AUTOSAR XML (schema 4-0-3)
package /ComponentTypes
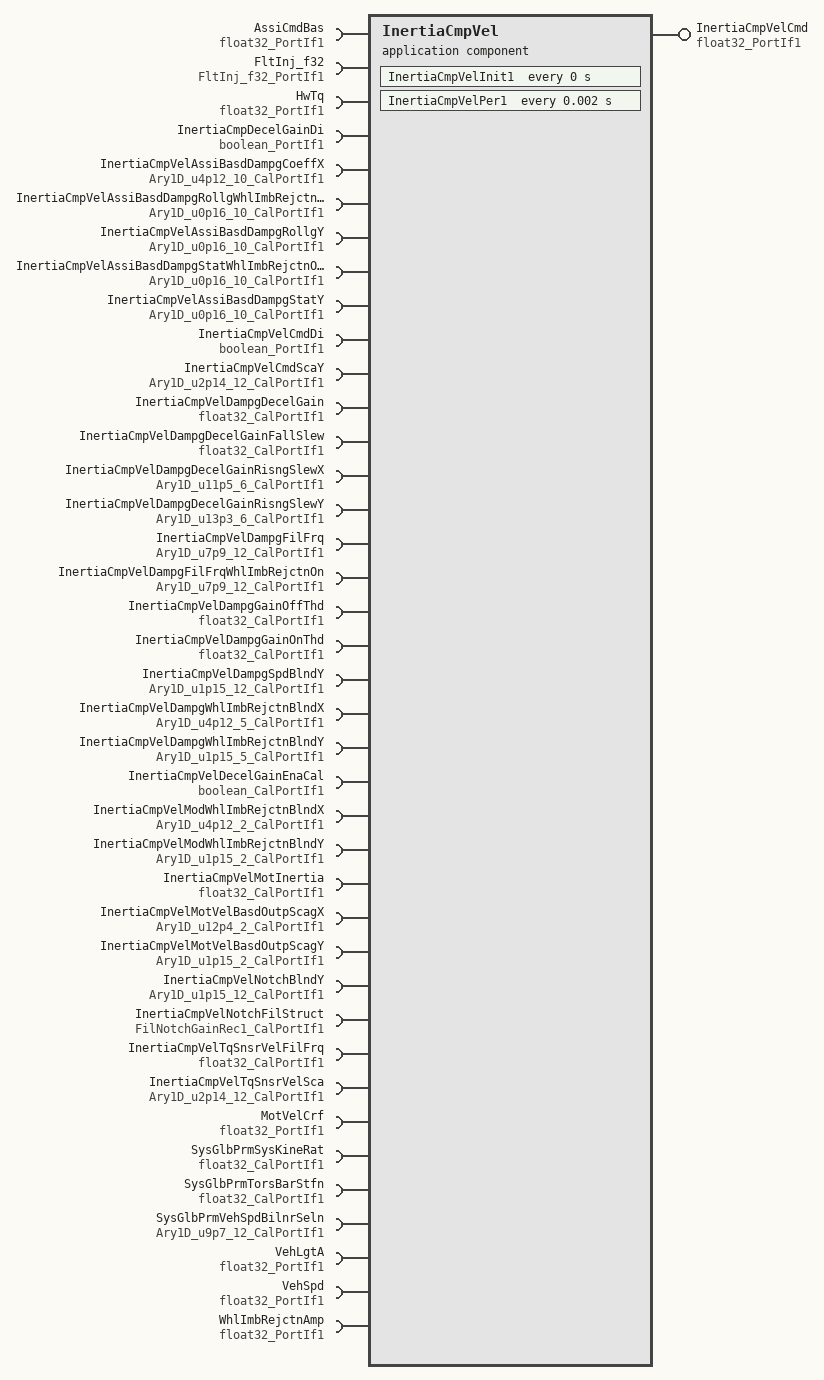
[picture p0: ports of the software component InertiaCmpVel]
  application sw component type InertiaCmpVel
    provide port InertiaCmpVelCmd: nonqueued-sender-com-spec{data-element=Val, init-value=0}, provided-interface=float32_PortIf1
    39 x require port:
      AssiCmdBas: nonqueued-receiver-com-spec{data-element=Val, filter=data-filter-type=ALWAYS, init-value=0}, required-interface=float32_PortIf1
      FltInj_f32: client-com-spec=Oper, required-interface=FltInj_f32_PortIf1
      HwTq: nonqueued-receiver-com-spec{data-element=Val, filter=data-filter-type=ALWAYS, init-value=0}, required-interface=float32_PortIf1
      InertiaCmpDecelGainDi: nonqueued-receiver-com-spec{data-element=Logl, filter=data-filter-type=ALWAYS, init-value=0}, required-interface=boolean_PortIf1
      InertiaCmpVelAssiBasdDampgCoeffX: parameter-require-com-spec{init-value=[0, 2048, 4096, 6144, 8192, 10240, 12288, 14336, 16384, 18432], parameter=Ary1D}, required-interface=Ary1D_u4p12_10_CalPortIf1
      InertiaCmpVelAssiBasdDampgRollgWhlImbRejctnOnY: parameter-require-com-spec{init-value=10 x 0, parameter=Ary1D}, required-interface=Ary1D_u0p16_10_CalPortIf1
      InertiaCmpVelAssiBasdDampgRollgY: parameter-require-com-spec{init-value=10 x 0, parameter=Ary1D}, required-interface=Ary1D_u0p16_10_CalPortIf1
      InertiaCmpVelAssiBasdDampgStatWhlImbRejctnOnY: parameter-require-com-spec{init-value=10 x 0, parameter=Ary1D}, required-interface=Ary1D_u0p16_10_CalPortIf1
      InertiaCmpVelAssiBasdDampgStatY: parameter-require-com-spec{init-value=10 x 0, parameter=Ary1D}, required-interface=Ary1D_u0p16_10_CalPortIf1
      InertiaCmpVelCmdDi: nonqueued-receiver-com-spec{data-element=Logl, filter=data-filter-type=ALWAYS, init-value=0}, required-interface=boolean_PortIf1
      InertiaCmpVelCmdScaY: parameter-require-com-spec{init-value=12 x 384, parameter=Ary1D}, required-interface=Ary1D_u2p14_12_CalPortIf1
      InertiaCmpVelDampgDecelGain: parameter-require-com-spec{init-value=1, parameter=Val}, required-interface=float32_CalPortIf1
      InertiaCmpVelDampgDecelGainFallSlew: parameter-require-com-spec{init-value=-4500, parameter=Val}, required-interface=float32_CalPortIf1
      InertiaCmpVelDampgDecelGainRisngSlewX: parameter-require-com-spec{init-value=[0, 640, 1088, 1120, 1152, 1184], parameter=Ary1D}, required-interface=Ary1D_u11p5_6_CalPortIf1
      InertiaCmpVelDampgDecelGainRisngSlewY: parameter-require-com-spec{init-value=6 x 36000, parameter=Ary1D}, required-interface=Ary1D_u13p3_6_CalPortIf1
      InertiaCmpVelDampgFilFrq: parameter-require-com-spec{init-value=12 x 8192, parameter=Ary1D}, required-interface=Ary1D_u7p9_12_CalPortIf1
      InertiaCmpVelDampgFilFrqWhlImbRejctnOn: parameter-require-com-spec{init-value=12 x 8192, parameter=Ary1D}, required-interface=Ary1D_u7p9_12_CalPortIf1
      InertiaCmpVelDampgGainOffThd: parameter-require-com-spec{init-value=1, parameter=Val}, required-interface=float32_CalPortIf1
      InertiaCmpVelDampgGainOnThd: parameter-require-com-spec{init-value=10, parameter=Val}, required-interface=float32_CalPortIf1
      InertiaCmpVelDampgSpdBlndY: parameter-require-com-spec{init-value=[32768, 32768, 9830, 6554, 3277, 0, 0, 0, 0, 0, 0, 0], parameter=Ary1D}, required-interface=Ary1D_u1p15_12_CalPortIf1
      InertiaCmpVelDampgWhlImbRejctnBlndX: parameter-require-com-spec{init-value=[208, 432, 640, 848, 1056], parameter=Ary1D}, required-interface=Ary1D_u4p12_5_CalPortIf1
      InertiaCmpVelDampgWhlImbRejctnBlndY: parameter-require-com-spec{init-value=5 x 0, parameter=Ary1D}, required-interface=Ary1D_u1p15_5_CalPortIf1
      InertiaCmpVelDecelGainEnaCal: parameter-require-com-spec{init-value=0, parameter=Logl}, required-interface=boolean_CalPortIf1
      InertiaCmpVelModWhlImbRejctnBlndX: parameter-require-com-spec{init-value=[0, 4096], parameter=Ary1D}, required-interface=Ary1D_u4p12_2_CalPortIf1
      InertiaCmpVelModWhlImbRejctnBlndY: parameter-require-com-spec{init-value=[32768, 0], parameter=Ary1D}, required-interface=Ary1D_u1p15_2_CalPortIf1
      InertiaCmpVelMotInertia: parameter-require-com-spec{init-value=0.001, parameter=Val}, required-interface=float32_CalPortIf1
      InertiaCmpVelMotVelBasdOutpScagX: parameter-require-com-spec{init-value=[1005, 1100], parameter=Ary1D}, required-interface=Ary1D_u12p4_2_CalPortIf1
      InertiaCmpVelMotVelBasdOutpScagY: parameter-require-com-spec{init-value=[32768, 32768], parameter=Ary1D}, required-interface=Ary1D_u1p15_2_CalPortIf1
      InertiaCmpVelNotchBlndY: parameter-require-com-spec{init-value=12 x 0, parameter=Ary1D}, required-interface=Ary1D_u1p15_12_CalPortIf1
      InertiaCmpVelNotchFilStruct: parameter-require-com-spec{init-value=fields=[FilGainB0:1, FilGainB1:-1.6346, FilGainB2:0.66799, FilGainA1:-1.6346, FilGainA2:0.66799], parameter=Rec}, required-interface=FilNotchGainRec1_CalPortIf1
      InertiaCmpVelTqSnsrVelFilFrq: parameter-require-com-spec{init-value=20, parameter=Val}, required-interface=float32_CalPortIf1
      InertiaCmpVelTqSnsrVelSca: parameter-require-com-spec{init-value=12 x 0, parameter=Ary1D}, required-interface=Ary1D_u2p14_12_CalPortIf1
      MotVelCrf: nonqueued-receiver-com-spec{data-element=Val, filter=data-filter-type=ALWAYS, init-value=0}, required-interface=float32_PortIf1
      SysGlbPrmSysKineRat: parameter-require-com-spec{init-value=22, parameter=Val}, required-interface=float32_CalPortIf1
      SysGlbPrmTorsBarStfn: parameter-require-com-spec{init-value=2.5, parameter=Val}, required-interface=float32_CalPortIf1
      SysGlbPrmVehSpdBilnrSeln: parameter-require-com-spec{init-value=[0, 640, 1920, 3840, 7680, 10240, 12800, 15360, 19200, 23040, 25600, 28160], parameter=Ary1D}, required-interface=Ary1D_u9p7_12_CalPortIf1
      VehLgtA: nonqueued-receiver-com-spec{data-element=Val, filter=data-filter-type=ALWAYS, init-value=0}, required-interface=float32_PortIf1
      VehSpd: nonqueued-receiver-com-spec{data-element=Val, filter=data-filter-type=ALWAYS, init-value=0}, required-interface=float32_PortIf1
      WhlImbRejctnAmp: nonqueued-receiver-com-spec{data-element=Val, filter=data-filter-type=ALWAYS, init-value=0}, required-interface=float32_PortIf1
    behavior InertiaCmpVel_InternalBehavior
      ar-typed-per-instance-memorys:
        20 x data, all with sw-calibration-access=READ-ONLY:
          DecelGain: type=float32
          dInertiaCmpVelAssiBasdDampgCoeff: type=float32
          dInertiaCmpVelCalcdInertiaCmp: type=float32
          dInertiaCmpVelFilFrq: type=float32
          dInertiaCmpVelMotVelBasdOutpScag: type=float32
          dInertiaCmpVelNotchBlndVal: type=float32
          dInertiaCmpVelNotchInpVal: type=float32
          dInertiaCmpVelNotchOutpVal: type=float32
          dInertiaCmpVelNotScadDrvrVel: type=float32
          dInertiaCmpVelRawDecelGain: type=float32
          dInertiaCmpVelScadDrvrVel: type=float32
          dInertiaCmpVelTqSnsrVelFildVal: type=float32
          NotchFilChk: type=boolean
          PreScagCmpCmdPrev1: type=float32
          PreScagCmpCmdPrev2: type=float32
          ScaDrvrVelPrev1: type=float32
          ScaDrvrVelPrev2: type=float32
          TqSnsrAgPrev: type=float32
          TqSnsrVelFil: type=FilLpRec1
          TqSnsrVelFilNotchSt: type=FilNotchStRec1
      timing event InertiaCmpVelInit1_InitEvent: start-on-event=InertiaCmpVelInit1, period=0
      timing event TMT_InertiaCmpVelPer1: start-on-event=InertiaCmpVelPer1, period=0.002
      runnable InertiaCmpVelInit1
      runnable InertiaCmpVelPer1
        data-receive-point-by-arguments:
          8 x access:
            REC_AssiCmdBas_Val: accessed-variable=AssiCmdBas.Val
            REC_HwTq_Val: accessed-variable=HwTq.Val
            REC_InertiaCmpDecelGainDi_Logl: accessed-variable=InertiaCmpDecelGainDi.Logl
            REC_InertiaCmpVelCmdDi_Logl: accessed-variable=InertiaCmpVelCmdDi.Logl
            REC_MotVelCrf_Val: accessed-variable=MotVelCrf.Val
            REC_VehLgtA_Val: accessed-variable=VehLgtA.Val
            REC_VehSpd_Val: accessed-variable=VehSpd.Val
            REC_WhlImbRejctnAmp_Val: accessed-variable=WhlImbRejctnAmp.Val
        data-send-points:
          access SEND_InertiaCmpVelCmd_Val: accessed-variable=InertiaCmpVelCmd.Val
        sync call SC_FltInj_f32_Oper: operation=FltInj_f32.Oper, timeout=0
  swc implementation InertiaCmpVel_Implementation: behavior=InertiaCmpVel_InternalBehavior
    code-descriptors:
      code Default: artifact-descriptors=autosar-engineering-object={short-label=Default, category=SWSRC}
